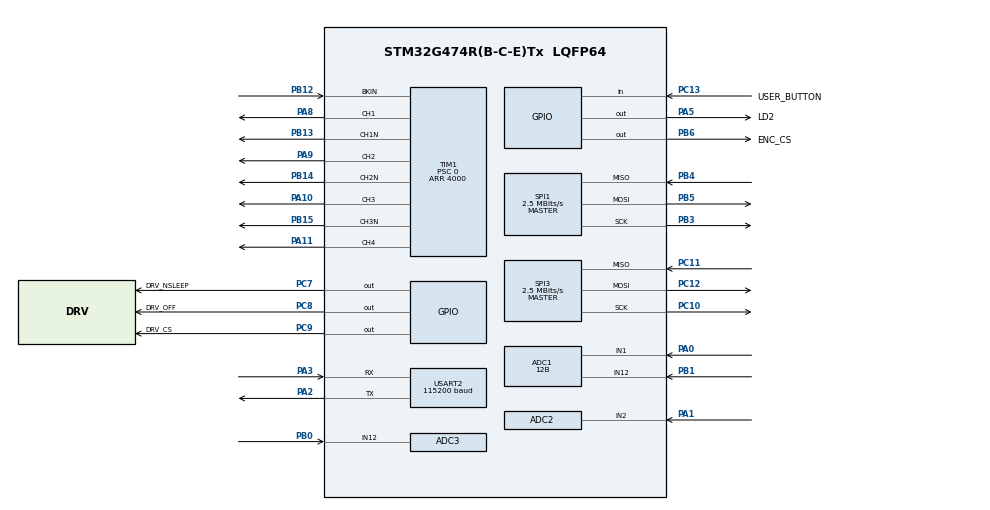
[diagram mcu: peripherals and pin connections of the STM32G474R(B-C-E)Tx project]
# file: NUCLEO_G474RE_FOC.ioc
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ADC1.Channel-1\#ChannelRegularConversion=ADC_CHANNEL_1
ADC1.ClockPrescaler=ADC_CLOCK_ASYNC_DIV1
ADC1.ContinuousConvMode=DISABLE
ADC1.DMAContinuousRequests=DISABLE
ADC1.DataAlign=ADC_DATAALIGN_RIGHT
ADC1.DiscontinuousConvMode=DISABLE
ADC1.EOCSelection=ADC_EOC_SINGLE_CONV
ADC1.EnableAnalogWatchDog1=false
ADC1.EnableAnalogWatchDog2=false
ADC1.EnableAnalogWatchDog3=false
ADC1.EnableInjectedConversion=ENABLE
ADC1.EnableInjectedOversampling=DISABLE
ADC1.EnableRegularConversion=ENABLE
ADC1.ExternalTrigConv=ADC_SOFTWARE_START
ADC1.ExternalTrigConvEdge=ADC_EXTERNALTRIGCONVEDGE_NONE
ADC1.ExternalTrigInjecConv=ADC_EXTERNALTRIGINJEC_T1_TRGO2
ADC1.ExternalTrigInjecConvEdge=ADC_EXTERNALTRIGINJECCONV_EDGE_RISING
ADC1.GainCompensation=0
ADC1.InjNumberOfConversion=2
ADC1.InjectedChannel-1\#ChannelInjectedConversion=ADC_CHANNEL_1
ADC1.InjectedChannel-2\#ChannelInjectedConversion=ADC_CHANNEL_12
ADC1.InjectedConvMode=None
ADC1.InjectedOffsetNumber-1\#ChannelInjectedConversion=ADC_OFFSET_NONE
ADC1.InjectedOffsetNumber-2\#ChannelInjectedConversion=ADC_OFFSET_NONE
ADC1.InjectedRank-1\#ChannelInjectedConversion=1
ADC1.InjectedRank-2\#ChannelInjectedConversion=2
ADC1.InjectedSamplingTime-1\#ChannelInjectedConversion=ADC_SAMPLETIME_12CYCLES_5
ADC1.InjectedSamplingTime-2\#ChannelInjectedConversion=ADC_SAMPLETIME_12CYCLES_5
ADC1.LowPowerAutoWait=DISABLE
ADC1.NbrOfConversion=1
ADC1.OffsetNumber-1\#ChannelRegularConversion=ADC_OFFSET_NONE
ADC1.Overrun=ADC_OVR_DATA_PRESERVED
ADC1.OversamplingMode=DISABLE
ADC1.Rank-1\#ChannelRegularConversion=1
ADC1.Resolution=ADC_RESOLUTION_12B
ADC1.SamplingTime-1\#ChannelRegularConversion=ADC_SAMPLETIME_12CYCLES_5
ADC1.ScanConvMode=ADC_SCAN_ENABLE
ADC1.injectedQueueMode=DISABLE
ADC1.master=1
ADC2.Channel-2\#ChannelRegularConversion=ADC_CHANNEL_2
ADC2.ClockPrescaler=ADC_CLOCK_ASYNC_DIV1
ADC2.ContinuousConvMode=DISABLE
ADC2.DMAContinuousRequests=DISABLE
ADC2.DataAlign=ADC_DATAALIGN_RIGHT
ADC2.DiscontinuousConvMode=DISABLE
ADC2.EOCSelection=ADC_EOC_SINGLE_CONV
ADC2.EnableAnalogWatchDog1=false
ADC2.EnableAnalogWatchDog2=false
ADC2.EnableAnalogWatchDog3=false
ADC2.EnableInjectedConversion=ENABLE
ADC2.EnableInjectedOversampling=DISABLE
ADC2.EnableRegularConversion=ENABLE
ADC2.ExternalTrigConv=ADC_SOFTWARE_START
ADC2.ExternalTrigConvEdge=ADC_EXTERNALTRIGCONVEDGE_NONE
ADC2.ExternalTrigInjecConv=ADC_EXTERNALTRIGINJEC_T1_TRGO2
ADC2.ExternalTrigInjecConvEdge=ADC_EXTERNALTRIGINJECCONV_EDGE_RISING
ADC2.GainCompensation=0
ADC2.InjNumberOfConversion=1
ADC2.InjectedChannel-1\#ChannelInjectedConversion=ADC_CHANNEL_2
ADC2.InjectedConvMode=None
ADC2.InjectedOffsetNumber-1\#ChannelInjectedConversion=ADC_OFFSET_NONE
ADC2.InjectedRank-1\#ChannelInjectedConversion=1
ADC2.InjectedSamplingTime-1\#ChannelInjectedConversion=ADC_SAMPLETIME_12CYCLES_5
ADC2.LowPowerAutoWait=DISABLE
ADC2.NbrOfConversion=1
ADC2.OffsetNumber-2\#ChannelRegularConversion=ADC_OFFSET_NONE
ADC2.Overrun=ADC_OVR_DATA_PRESERVED
ADC2.OversamplingMode=DISABLE
ADC2.Rank-2\#ChannelRegularConversion=1
ADC2.Resolution=ADC_RESOLUTION_12B
ADC2.SamplingTime-2\#ChannelRegularConversion=ADC_SAMPLETIME_12CYCLES_5
ADC2.ScanConvMode=ADC_SCAN_DISABLE
ADC2.injectedQueueMode=DISABLE
ADC3.Channel-12\#ChannelRegularConversion=ADC_CHANNEL_12
ADC3.ClockPrescaler=ADC_CLOCK_ASYNC_DIV1
ADC3.ContinuousConvMode=DISABLE
ADC3.DMAContinuousRequests=DISABLE
ADC3.DataAlign=ADC_DATAALIGN_RIGHT
ADC3.DiscontinuousConvMode=DISABLE
ADC3.EOCSelection=ADC_EOC_SINGLE_CONV
ADC3.EnableAnalogWatchDog1=false
ADC3.EnableAnalogWatchDog2=false
ADC3.EnableAnalogWatchDog3=false
ADC3.EnableInjectedConversion=ENABLE
ADC3.EnableInjectedOversampling=DISABLE
ADC3.EnableRegularConversion=ENABLE
ADC3.ExternalTrigConv=ADC_SOFTWARE_START
ADC3.ExternalTrigConvEdge=ADC_EXTERNALTRIGCONVEDGE_NONE
ADC3.ExternalTrigInjecConv=ADC_EXTERNALTRIGINJEC_T1_TRGO2
ADC3.ExternalTrigInjecConvEdge=ADC_EXTERNALTRIGINJECCONV_EDGE_RISING
ADC3.GainCompensation=0
ADC3.InjNumberOfConversion=1
ADC3.InjectedChannel-1\#ChannelInjectedConversion=ADC_CHANNEL_12
ADC3.InjectedConvMode=None
ADC3.InjectedOffsetNumber-1\#ChannelInjectedConversion=ADC_OFFSET_NONE
ADC3.InjectedRank-1\#ChannelInjectedConversion=1
ADC3.InjectedSamplingTime-1\#ChannelInjectedConversion=ADC_SAMPLETIME_12CYCLES_5
ADC3.LowPowerAutoWait=DISABLE
ADC3.NbrOfConversion=1
ADC3.OffsetNumber-12\#ChannelRegularConversion=ADC_OFFSET_NONE
ADC3.Overrun=ADC_OVR_DATA_PRESERVED
ADC3.OversamplingMode=DISABLE
ADC3.Rank-12\#ChannelRegularConversion=1
ADC3.Resolution=ADC_RESOLUTION_12B
ADC3.SamplingTime-12\#ChannelRegularConversion=ADC_SAMPLETIME_12CYCLES_5
ADC3.ScanConvMode=ADC_SCAN_DISABLE
ADC3.injectedQueueMode=DISABLE
ADC3.master=1
IWDG.Prescaler=IWDG_PRESCALER_32
IWDG.Reload=127
IWDG.Window=4095
Mcu.Family=STM32G4
Mcu.Name=STM32G474R(B-C-E)Tx
Mcu.Package=LQFP64
NVIC.ADC1_2_IRQn=true\:1\:0\:false\:false\:true\:true\:true\:true
NVIC.PriorityGroup=NVIC_PRIORITYGROUP_4
NVIC.TIM1_BRK_TIM15_IRQn=true\:0\:0\:false\:false\:true\:true\:true\:true
NVIC.TIM6_DAC_IRQn=true\:2\:0\:false\:false\:true\:true\:true\:true
NVIC.USART2_IRQn=true\:4\:0\:false\:false\:true\:true\:true\:true
PA0.Mode=IN1-Single-Ended
PA0.Signal=ADC1_IN1
PA1.Mode=IN2-Single-Ended
PA1.Signal=ADC2_IN2
PA10.GPIO_Speed=GPIO_SPEED_FREQ_VERY_HIGH
PA10.Signal=S_TIM1_CH3
PA11.GPIO_Speed=GPIO_SPEED_FREQ_VERY_HIGH
PA11.Signal=S_TIM1_CH4
PA13.Mode=Serial_Wire
PA13.Signal=SYS_JTMS-SWDIO
PA14.Mode=Serial_Wire
PA14.Signal=SYS_JTCK-SWCLK
PA2.Mode=Asynchronous
PA2.Signal=USART2_TX
PA3.Mode=Asynchronous
PA3.Signal=USART2_RX
PA5.GPIO_Label=LD2
PA5.Signal=GPIO_Output
PA8.GPIO_Speed=GPIO_SPEED_FREQ_VERY_HIGH
PA8.Signal=S_TIM1_CH1
PA9.GPIO_Speed=GPIO_SPEED_FREQ_VERY_HIGH
PA9.Signal=S_TIM1_CH2
PB0.Mode=IN12-Single-Ended
PB0.Signal=ADC3_IN12
PB1.Mode=IN12-Single-Ended
PB1.Signal=ADC1_IN12
PB12.GPIO_PuPd=GPIO_PULLUP
PB12.Mode=Activate-Break-Input
PB12.Signal=TIM1_BKIN
PB13.GPIO_Speed=GPIO_SPEED_FREQ_VERY_HIGH
PB13.Mode=PWM Generation1 CH1 CH1N
PB13.Signal=TIM1_CH1N
PB14.GPIO_Speed=GPIO_SPEED_FREQ_VERY_HIGH
PB14.Mode=PWM Generation2 CH2 CH2N
PB14.Signal=TIM1_CH2N
PB15.GPIO_Speed=GPIO_SPEED_FREQ_VERY_HIGH
PB15.Mode=PWM Generation3 CH3 CH3N
PB15.Signal=TIM1_CH3N
PB3.GPIO_PuPd=GPIO_PULLDOWN
PB3.GPIO_Speed=GPIO_SPEED_FREQ_VERY_HIGH
PB3.Mode=Full_Duplex_Master
PB3.Signal=SPI1_SCK
PB4.GPIO_PuPd=GPIO_PULLDOWN
PB4.GPIO_Speed=GPIO_SPEED_FREQ_VERY_HIGH
PB4.Mode=Full_Duplex_Master
PB4.Signal=SPI1_MISO
PB5.GPIO_PuPd=GPIO_PULLDOWN
PB5.GPIO_Speed=GPIO_SPEED_FREQ_VERY_HIGH
PB5.Mode=Full_Duplex_Master
PB5.Signal=SPI1_MOSI
PB6.GPIO_Label=ENC_CS
PB6.GPIO_Speed=GPIO_SPEED_FREQ_HIGH
PB6.PinState=GPIO_PIN_SET
PB6.Signal=GPIO_Output
PC10.GPIO_PuPd=GPIO_PULLDOWN
PC10.GPIO_Speed=GPIO_SPEED_FREQ_LOW
PC10.Mode=Full_Duplex_Master
PC10.Signal=SPI3_SCK
PC11.GPIO_PuPd=GPIO_PULLDOWN
PC11.GPIO_Speed=GPIO_SPEED_FREQ_VERY_HIGH
PC11.Mode=Full_Duplex_Master
PC11.Signal=SPI3_MISO
PC12.GPIO_PuPd=GPIO_PULLDOWN
PC12.GPIO_Speed=GPIO_SPEED_FREQ_LOW
PC12.Mode=Full_Duplex_Master
PC12.Signal=SPI3_MOSI
PC13.GPIO_Label=USER_BUTTON
PC13.Signal=GPIO_Input
PC7.GPIO_Label=DRV_NSLEEP
PC7.GPIO_Speed=GPIO_SPEED_FREQ_HIGH
PC7.PinState=GPIO_PIN_RESET
PC7.Signal=GPIO_Output
PC8.GPIO_Label=DRV_OFF
PC8.GPIO_Speed=GPIO_SPEED_FREQ_HIGH
PC8.PinState=GPIO_PIN_SET
PC8.Signal=GPIO_Output
PC9.GPIO_Label=DRV_CS
PC9.GPIO_Speed=GPIO_SPEED_FREQ_HIGH
PC9.PinState=GPIO_PIN_SET
PC9.Signal=GPIO_Output
ProjectManager.HeapSize=0x200
ProjectManager.StackSize=0x1800
ProjectManager.TargetToolchain=MDK-ARM V5.32
RCC.ADC12ClockSelection=RCC_ADC12CLKSOURCE_PLL
RCC.ADC12Freq_Value=40000000
RCC.ADC345ClockSelection=RCC_ADC345CLKSOURCE_PLL
RCC.ADC345Freq_Value=40000000
RCC.AHBFreq_Value=160000000
RCC.APB1CLKDivider=RCC_HCLK_DIV2
RCC.APB1Freq_Value=80000000
RCC.APB1TimFreq_Value=160000000
RCC.APB2Freq_Value=160000000
RCC.APB2TimFreq_Value=160000000
RCC.CortexFreq_Value=160000000
RCC.EXTERNAL_CLOCK_VALUE=12288000
RCC.HCLKFreq_Value=160000000
RCC.HSE_VALUE=8000000
RCC.HSI48_VALUE=48000000
RCC.HSI_VALUE=16000000
RCC.LSE_VALUE=32768
RCC.PLLM=RCC_PLLM_DIV4
RCC.PLLN=80
RCC.PLLP=RCC_PLLP_DIV8
RCC.PLLQ=RCC_PLLQ_DIV2
RCC.PLLSourceVirtual=RCC_PLLSOURCE_HSI
RCC.SYSCLKFreq_VALUE=160000000
RCC.SYSCLKSource=RCC_SYSCLKSOURCE_PLLCLK
RCC.USBFreq_Value=160000000
RCC.VCOOutputFreq_Value=320000000
SH.S_TIM1_CH1.0=TIM1_CH1,PWM Generation1 CH1 CH1N
SH.S_TIM1_CH2.0=TIM1_CH2,PWM Generation2 CH2 CH2N
SH.S_TIM1_CH3.0=TIM1_CH3,PWM Generation3 CH3 CH3N
SH.S_TIM1_CH4.0=TIM1_CH4,PWM Generation4 CH4
SPI1.BaudRatePrescaler=SPI_BAUDRATEPRESCALER_64
SPI1.CLKPhase=SPI_PHASE_2EDGE
SPI1.CLKPolarity=SPI_POLARITY_LOW
SPI1.CRCCalculation=SPI_CRCCALCULATION_DISABLE
SPI1.CalculateBaudRate=2.5 MBits/s
SPI1.DataSize=SPI_DATASIZE_16BIT
SPI1.Direction=SPI_DIRECTION_2LINES
SPI1.FirstBit=SPI_FIRSTBIT_MSB
SPI1.Mode=SPI_MODE_MASTER
SPI1.NSS=SPI_NSS_SOFT
SPI1.TIMode=SPI_TIMODE_DISABLE
SPI1.VirtualType=VM_MASTER
SPI3.BaudRatePrescaler=SPI_BAUDRATEPRESCALER_32
SPI3.CLKPhase=SPI_PHASE_2EDGE
SPI3.CLKPolarity=SPI_POLARITY_LOW
SPI3.CRCCalculation=SPI_CRCCALCULATION_DISABLE
SPI3.CalculateBaudRate=2.5 MBits/s
SPI3.DataSize=SPI_DATASIZE_16BIT
SPI3.Direction=SPI_DIRECTION_2LINES
SPI3.FirstBit=SPI_FIRSTBIT_MSB
SPI3.Mode=SPI_MODE_MASTER
SPI3.NSS=SPI_NSS_SOFT
SPI3.TIMode=SPI_TIMODE_DISABLE
SPI3.VirtualType=VM_MASTER
TIM1.AsymmetricalDeadTime=DISABLE
TIM1.AutoReloadPreload=TIM_AUTORELOAD_PRELOAD_DISABLE
TIM1.AutomaticOutput=TIM_AUTOMATICOUTPUT_DISABLE
TIM1.Break2Filter=0
TIM1.Break2Polarity=TIM_BREAK2POLARITY_HIGH
TIM1.Break2State=TIM_BREAK2_DISABLE
TIM1.BreakAFMode=TIM_BREAK_AFMODE_INPUT
TIM1.BreakFilter=0
TIM1.BreakPolarity=TIM_BREAKPOLARITY_LOW
TIM1.BreakState=TIM_BREAK_ENABLE
TIM1.Channel-PWM\ Generation1\ CH1\ CH1N=TIM_CHANNEL_1
TIM1.Channel-PWM\ Generation2\ CH2\ CH2N=TIM_CHANNEL_2
TIM1.Channel-PWM\ Generation3\ CH3\ CH3N=TIM_CHANNEL_3
TIM1.Channel-PWM\ Generation4\ CH4=TIM_CHANNEL_4
TIM1.ClearInputSource=TIM_CLEARINPUTSOURCE_NONE
TIM1.ClockDivision=TIM_CLOCKDIVISION_DIV1
TIM1.CounterMode=TIM_COUNTERMODE_CENTERALIGNED1
TIM1.DeadTime=80
TIM1.DeadTimePreload=DISABLE
TIM1.Dithering=Disable
TIM1.LockLevel=TIM_LOCKLEVEL_OFF
TIM1.OCFastMode_PWM-PWM\ Generation1\ CH1\ CH1N=TIM_OCFAST_DISABLE
TIM1.OCFastMode_PWM-PWM\ Generation2\ CH2\ CH2N=TIM_OCFAST_DISABLE
TIM1.OCFastMode_PWM-PWM\ Generation3\ CH3\ CH3N=TIM_OCFAST_DISABLE
TIM1.OCFastMode_PWM-PWM\ Generation4\ CH4=TIM_OCFAST_DISABLE
TIM1.OCIdleState_1=TIM_OCIDLESTATE_RESET
TIM1.OCIdleState_2=TIM_OCIDLESTATE_RESET
TIM1.OCIdleState_3=TIM_OCIDLESTATE_RESET
TIM1.OCIdleState_4=TIM_OCIDLESTATE_RESET
TIM1.OCMode_PWM-PWM\ Generation1\ CH1\ CH1N=TIM_OCMODE_PWM1
TIM1.OCMode_PWM-PWM\ Generation2\ CH2\ CH2N=TIM_OCMODE_PWM1
TIM1.OCMode_PWM-PWM\ Generation3\ CH3\ CH3N=TIM_OCMODE_PWM1
TIM1.OCMode_PWM-PWM\ Generation4\ CH4=TIM_OCMODE_PWM2
TIM1.OCNIdleState_1=TIM_OCNIDLESTATE_RESET
TIM1.OCNIdleState_2=TIM_OCNIDLESTATE_RESET
TIM1.OCNIdleState_3=TIM_OCNIDLESTATE_RESET
TIM1.OCNPolarity_1=TIM_OCNPOLARITY_HIGH
TIM1.OCNPolarity_2=TIM_OCNPOLARITY_HIGH
TIM1.OCNPolarity_3=TIM_OCNPOLARITY_HIGH
TIM1.OCPolarity_1=TIM_OCPOLARITY_HIGH
TIM1.OCPolarity_2=TIM_OCPOLARITY_HIGH
TIM1.OCPolarity_3=TIM_OCPOLARITY_HIGH
TIM1.OCPolarity_4=TIM_OCPOLARITY_HIGH
TIM1.OffStateIDLEMode=TIM_OSSI_ENABLE
TIM1.OffStateRunMode=TIM_OSSR_ENABLE
TIM1.PeriodNoDither=4000
TIM1.Prescaler=0
TIM1.PulseNoDither_1=2000
TIM1.PulseNoDither_2=2000
TIM1.PulseNoDither_3=2000
TIM1.PulseNoDither_4=3900
TIM1.RepetitionCounter=0
TIM1.SourceBRK2COMP1=TIM_BREAKINPUTSOURCE_DISABLE
TIM1.SourceBRK2COMP2=TIM_BREAKINPUTSOURCE_DISABLE
TIM1.SourceBRK2COMP3=TIM_BREAKINPUTSOURCE_DISABLE
TIM1.SourceBRK2COMP4=TIM_BREAKINPUTSOURCE_DISABLE
TIM1.SourceBRK2COMP5=TIM_BREAKINPUTSOURCE_DISABLE
TIM1.SourceBRK2COMP6=TIM_BREAKINPUTSOURCE_DISABLE
TIM1.SourceBRK2COMP7=TIM_BREAKINPUTSOURCE_DISABLE
TIM1.SourceBRK2DigInput=TIM_BREAKINPUTSOURCE_DISABLE
TIM1.SourceBRKCOMP1=TIM_BREAKINPUTSOURCE_DISABLE
TIM1.SourceBRKCOMP2=TIM_BREAKINPUTSOURCE_DISABLE
TIM1.SourceBRKCOMP3=TIM_BREAKINPUTSOURCE_DISABLE
TIM1.SourceBRKCOMP4=TIM_BREAKINPUTSOURCE_DISABLE
TIM1.SourceBRKCOMP5=TIM_BREAKINPUTSOURCE_DISABLE
TIM1.SourceBRKCOMP6=TIM_BREAKINPUTSOURCE_DISABLE
TIM1.SourceBRKCOMP7=TIM_BREAKINPUTSOURCE_DISABLE
TIM1.SourceBRKDigInput=TIM_BREAKINPUTSOURCE_ENABLE
TIM1.SourceBRKDigInputPolarity=TIM_BREAKINPUTSOURCE_POLARITY_HIGH
TIM1.TIM_MasterOutputTrigger=TIM_TRGO_RESET
TIM1.TIM_MasterOutputTrigger2=TIM_TRGO2_OC4REF
TIM1.TIM_MasterSlaveMode=TIM_MASTERSLAVEMODE_DISABLE
TIM2.AutoReloadPreload=TIM_AUTORELOAD_PRELOAD_DISABLE
TIM2.ClockDivision=TIM_CLOCKDIVISION_DIV1
TIM2.CounterMode=TIM_COUNTERMODE_UP
TIM2.Period=4294967295
TIM2.Prescaler=159
TIM2.TIM_MasterOutputTrigger=TIM_TRGO_RESET
TIM2.TIM_MasterSlaveMode=TIM_MASTERSLAVEMODE_DISABLE
TIM2.TIM_SlaveMode=TIM_SLAVEMODE_DISABLE
TIM6.AutoReloadPreload=TIM_AUTORELOAD_PRELOAD_DISABLE
TIM6.Period=249
TIM6.Prescaler=159
USART2.BaudRate=115200
USART2.VirtualMode-Asynchronous=VM_ASYNC
VP_IWDG_VS_IWDG.Mode=IWDG_Activate
VP_SYS_VS_DBSignals.Mode=DisableDeadBatterySignals
VP_TIM2_VS_ClockSourceINT.Mode=Internal
VP_TIM6_VS_ClockSourceINT.Mode=Enable_Timer
board=custom

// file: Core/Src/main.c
/* USER CODE BEGIN Header */
/**
  ******************************************************************************
  * @file           : main.c
  * @brief          : Main program body
  ******************************************************************************
  * @attention
  *
  * Copyright (c) 2026 STMicroelectronics.
  * All rights reserved.
  *
  * This software is licensed under terms that can be found in the LICENSE file
  * in the root directory of this software component.
  * If no LICENSE file comes with this software, it is provided AS-IS.
  *
  ******************************************************************************
  */
/* USER CODE END Header */
#include "main.h"

/* USER CODE BEGIN Includes */
#include "bench_app.h"
/* USER CODE END Includes */

void SystemClock_Config(void);
static void MX_GPIO_Init(void);
static void MX_USART2_UART_Init(void);
static void MX_SPI1_Init(void);
static void MX_SPI3_Init(void);
static void MX_ADC1_Init(void);
static void MX_ADC2_Init(void);
static void MX_ADC3_Init(void);
static void MX_TIM1_Init(void);
static void MX_TIM2_Init(void);
static void MX_TIM6_Init(void);
static void MX_IWDG_Init(void);

int main(void)
{

  /* MCU Configuration--------------------------------------------------------*/

  /* Reset of all peripherals, Initializes the Flash interface and the Systick. */
  LL_APB2_GRP1_EnableClock(LL_APB2_GRP1_PERIPH_SYSCFG);
  LL_APB1_GRP1_EnableClock(LL_APB1_GRP1_PERIPH_PWR);

  /* System interrupt init*/
  NVIC_SetPriorityGrouping(NVIC_PRIORITYGROUP_4);

  /* SysTick_IRQn interrupt configuration */
  NVIC_SetPriority(SysTick_IRQn, NVIC_EncodePriority(NVIC_GetPriorityGrouping(),3, 0));

  /** Disable the internal Pull-Up in Dead Battery pins of UCPD peripheral
  */
  LL_PWR_DisableUCPDDeadBattery();

  /* Configure the system clock */
  SystemClock_Config();

  /* Initialize all configured peripherals */
  MX_GPIO_Init();
  MX_USART2_UART_Init();
  MX_SPI1_Init();
  MX_SPI3_Init();
  MX_ADC1_Init();
  MX_ADC2_Init();
  MX_ADC3_Init();
  MX_TIM1_Init();
  MX_TIM2_Init();
  MX_TIM6_Init();
  MX_IWDG_Init();
  /* USER CODE BEGIN 2 */
  Bench_Init();
  /* USER CODE END 2 */

  /* Infinite loop */
  while (1)
  {

    /* USER CODE BEGIN 3 */
    Bench_Loop();
  }
  /* USER CODE END 3 */
}

void SystemClock_Config(void)
{
  LL_FLASH_SetLatency(LL_FLASH_LATENCY_4);
  while(LL_FLASH_GetLatency() != LL_FLASH_LATENCY_4)
  {
  }
  LL_PWR_EnableRange1BoostMode();
  LL_RCC_HSI_Enable();
   /* Wait till HSI is ready */
  while(LL_RCC_HSI_IsReady() != 1)
  {
  }

  LL_RCC_HSI_SetCalibTrimming(64);
  LL_RCC_LSI_Enable();
   /* Wait till LSI is ready */
  while(LL_RCC_LSI_IsReady() != 1)
  {
  }

  LL_RCC_PLL_ConfigDomain_SYS(LL_RCC_PLLSOURCE_HSI, LL_RCC_PLLM_DIV_4, 80, LL_RCC_PLLR_DIV_2);
  /* ES0430 2.7.11: concurrent ADCs share PLLP, with no ADC prescaling.
   * Keep the ADC at 40 MHz and TIM1 at 160 MHz (20 kHz PWM). */
  LL_RCC_PLL_ConfigDomain_ADC(LL_RCC_PLLSOURCE_HSI, LL_RCC_PLLM_DIV_4, 80, LL_RCC_PLLP_DIV_8);
  LL_RCC_PLL_EnableDomain_ADC();
  LL_RCC_PLL_EnableDomain_SYS();
  LL_RCC_PLL_Enable();
   /* Wait till PLL is ready */
  while(LL_RCC_PLL_IsReady() != 1)
  {
  }

  LL_RCC_SetSysClkSource(LL_RCC_SYS_CLKSOURCE_PLL);
  LL_RCC_SetAHBPrescaler(LL_RCC_SYSCLK_DIV_2);
   /* Wait till System clock is ready */
  while(LL_RCC_GetSysClkSource() != LL_RCC_SYS_CLKSOURCE_STATUS_PLL)
  {
  }

  /* Insure 1us transition state at intermediate medium speed clock*/
  for (__IO uint32_t i = (170 >> 1); i !=0; i--);

  /* Set AHB prescaler*/
  LL_RCC_SetAHBPrescaler(LL_RCC_SYSCLK_DIV_1);
  LL_RCC_SetAPB1Prescaler(LL_RCC_APB1_DIV_2);
  LL_RCC_SetAPB2Prescaler(LL_RCC_APB2_DIV_1);

  LL_Init1msTick(160000000);

  LL_SetSystemCoreClock(160000000);
}

static void MX_ADC1_Init(void)
{

  LL_ADC_InitTypeDef ADC_InitStruct = {0};
  LL_ADC_REG_InitTypeDef ADC_REG_InitStruct = {0};
  LL_ADC_CommonInitTypeDef ADC_CommonInitStruct = {0};
  LL_ADC_INJ_InitTypeDef ADC_INJ_InitStruct = {0};

  LL_GPIO_InitTypeDef GPIO_InitStruct = {0};

  LL_RCC_SetADCClockSource(LL_RCC_ADC12_CLKSOURCE_PLL);

  /* Peripheral clock enable */
  LL_AHB2_GRP1_EnableClock(LL_AHB2_GRP1_PERIPH_ADC12);

  LL_AHB2_GRP1_EnableClock(LL_AHB2_GRP1_PERIPH_GPIOA);
  LL_AHB2_GRP1_EnableClock(LL_AHB2_GRP1_PERIPH_GPIOB);
  /**ADC1 GPIO Configuration
  PA0   ------> ADC1_IN1
  PB1   ------> ADC1_IN12
  */
  GPIO_InitStruct.Pin = LL_GPIO_PIN_0;
  GPIO_InitStruct.Mode = LL_GPIO_MODE_ANALOG;
  GPIO_InitStruct.Pull = LL_GPIO_PULL_NO;
  LL_GPIO_Init(GPIOA, &GPIO_InitStruct);

  GPIO_InitStruct.Pin = LL_GPIO_PIN_1;
  GPIO_InitStruct.Mode = LL_GPIO_MODE_ANALOG;
  GPIO_InitStruct.Pull = LL_GPIO_PULL_NO;
  LL_GPIO_Init(GPIOB, &GPIO_InitStruct);

  /* ADC1 interrupt Init */
  NVIC_SetPriority(ADC1_2_IRQn, NVIC_EncodePriority(NVIC_GetPriorityGrouping(),1, 0));
  NVIC_EnableIRQ(ADC1_2_IRQn);

  /** Common config
  */
  ADC_InitStruct.Resolution = LL_ADC_RESOLUTION_12B;
  ADC_InitStruct.DataAlignment = LL_ADC_DATA_ALIGN_RIGHT;
  ADC_InitStruct.LowPowerMode = LL_ADC_LP_MODE_NONE;
  LL_ADC_Init(ADC1, &ADC_InitStruct);
  ADC_REG_InitStruct.TriggerSource = LL_ADC_REG_TRIG_SOFTWARE;
  ADC_REG_InitStruct.SequencerLength = LL_ADC_REG_SEQ_SCAN_DISABLE;
  ADC_REG_InitStruct.SequencerDiscont = LL_ADC_REG_SEQ_DISCONT_DISABLE;
  ADC_REG_InitStruct.ContinuousMode = LL_ADC_REG_CONV_SINGLE;
  ADC_REG_InitStruct.DMATransfer = LL_ADC_REG_DMA_TRANSFER_NONE;
  ADC_REG_InitStruct.Overrun = LL_ADC_REG_OVR_DATA_PRESERVED;
  LL_ADC_REG_Init(ADC1, &ADC_REG_InitStruct);
  LL_ADC_SetGainCompensation(ADC1, 0);
  LL_ADC_SetOverSamplingScope(ADC1, LL_ADC_OVS_DISABLE);
  ADC_CommonInitStruct.CommonClock = LL_ADC_CLOCK_ASYNC_DIV1;
  ADC_CommonInitStruct.Multimode = LL_ADC_MULTI_INDEPENDENT;
  LL_ADC_CommonInit(__LL_ADC_COMMON_INSTANCE(ADC1), &ADC_CommonInitStruct);
  ADC_INJ_InitStruct.TriggerSource = LL_ADC_INJ_TRIG_EXT_TIM1_TRGO2;
  ADC_INJ_InitStruct.SequencerLength = LL_ADC_INJ_SEQ_SCAN_ENABLE_2RANKS;
  ADC_INJ_InitStruct.SequencerDiscont = LL_ADC_INJ_SEQ_DISCONT_DISABLE;
  ADC_INJ_InitStruct.TrigAuto = LL_ADC_INJ_TRIG_INDEPENDENT;
  LL_ADC_INJ_Init(ADC1, &ADC_INJ_InitStruct);
  LL_ADC_INJ_SetQueueMode(ADC1, LL_ADC_INJ_QUEUE_DISABLE);
  LL_ADC_INJ_SetTriggerEdge(ADC1, LL_ADC_INJ_TRIG_EXT_RISING);

  /* Disable ADC deep power down (enabled by default after reset state) */
  LL_ADC_DisableDeepPowerDown(ADC1);
  /* Enable ADC internal voltage regulator */
  LL_ADC_EnableInternalRegulator(ADC1);
  /* Delay for ADC internal voltage regulator stabilization. */
  /* Compute number of CPU cycles to wait for, from delay in us. */
  /* Note: Variable divided by 2 to compensate partially */
  /* CPU processing cycles (depends on compilation optimization). */
  /* Note: If system core clock frequency is below 200kHz, wait time */
  /* is only a few CPU processing cycles. */
  uint32_t wait_loop_index;
  wait_loop_index = ((LL_ADC_DELAY_INTERNAL_REGUL_STAB_US * (SystemCoreClock / (100000 * 2))) / 10);
  while(wait_loop_index != 0)
  {
    wait_loop_index--;
  }

  /** Configure Injected Channel
  */
  LL_ADC_INJ_SetSequencerRanks(ADC1, LL_ADC_INJ_RANK_1, LL_ADC_CHANNEL_1);
  LL_ADC_SetChannelSamplingTime(ADC1, LL_ADC_CHANNEL_1, LL_ADC_SAMPLINGTIME_12CYCLES_5);
  LL_ADC_SetChannelSingleDiff(ADC1, LL_ADC_CHANNEL_1, LL_ADC_SINGLE_ENDED);

  /** Configure Injected Channel
  */
  LL_ADC_INJ_SetSequencerRanks(ADC1, LL_ADC_INJ_RANK_2, LL_ADC_CHANNEL_12);
  LL_ADC_SetChannelSamplingTime(ADC1, LL_ADC_CHANNEL_12, LL_ADC_SAMPLINGTIME_12CYCLES_5);
  LL_ADC_SetChannelSingleDiff(ADC1, LL_ADC_CHANNEL_12, LL_ADC_SINGLE_ENDED);

  /** Configure Regular Channel
  */
  LL_ADC_REG_SetSequencerRanks(ADC1, LL_ADC_REG_RANK_1, LL_ADC_CHANNEL_1);
  LL_ADC_SetChannelSamplingTime(ADC1, LL_ADC_CHANNEL_1, LL_ADC_SAMPLINGTIME_12CYCLES_5);
  LL_ADC_SetChannelSingleDiff(ADC1, LL_ADC_CHANNEL_1, LL_ADC_SINGLE_ENDED);

}

static void MX_ADC2_Init(void)
{

  LL_ADC_InitTypeDef ADC_InitStruct = {0};
  LL_ADC_REG_InitTypeDef ADC_REG_InitStruct = {0};
  LL_ADC_INJ_InitTypeDef ADC_INJ_InitStruct = {0};

  LL_GPIO_InitTypeDef GPIO_InitStruct = {0};

  LL_RCC_SetADCClockSource(LL_RCC_ADC12_CLKSOURCE_PLL);

  /* Peripheral clock enable */
  LL_AHB2_GRP1_EnableClock(LL_AHB2_GRP1_PERIPH_ADC12);

  LL_AHB2_GRP1_EnableClock(LL_AHB2_GRP1_PERIPH_GPIOA);
  /**ADC2 GPIO Configuration
  PA1   ------> ADC2_IN2
  */
  GPIO_InitStruct.Pin = LL_GPIO_PIN_1;
  GPIO_InitStruct.Mode = LL_GPIO_MODE_ANALOG;
  GPIO_InitStruct.Pull = LL_GPIO_PULL_NO;
  LL_GPIO_Init(GPIOA, &GPIO_InitStruct);

  /* ADC2 interrupt Init */
  NVIC_SetPriority(ADC1_2_IRQn, NVIC_EncodePriority(NVIC_GetPriorityGrouping(),1, 0));
  NVIC_EnableIRQ(ADC1_2_IRQn);

  /** Common config
  */
  ADC_InitStruct.Resolution = LL_ADC_RESOLUTION_12B;
  ADC_InitStruct.DataAlignment = LL_ADC_DATA_ALIGN_RIGHT;
  ADC_InitStruct.LowPowerMode = LL_ADC_LP_MODE_NONE;
  LL_ADC_Init(ADC2, &ADC_InitStruct);
  ADC_REG_InitStruct.TriggerSource = LL_ADC_REG_TRIG_SOFTWARE;
  ADC_REG_InitStruct.SequencerLength = LL_ADC_REG_SEQ_SCAN_DISABLE;
  ADC_REG_InitStruct.SequencerDiscont = LL_ADC_REG_SEQ_DISCONT_DISABLE;
  ADC_REG_InitStruct.ContinuousMode = LL_ADC_REG_CONV_SINGLE;
  ADC_REG_InitStruct.DMATransfer = LL_ADC_REG_DMA_TRANSFER_NONE;
  ADC_REG_InitStruct.Overrun = LL_ADC_REG_OVR_DATA_PRESERVED;
  LL_ADC_REG_Init(ADC2, &ADC_REG_InitStruct);
  LL_ADC_SetGainCompensation(ADC2, 0);
  LL_ADC_SetOverSamplingScope(ADC2, LL_ADC_OVS_DISABLE);
  ADC_INJ_InitStruct.TriggerSource = LL_ADC_INJ_TRIG_EXT_TIM1_TRGO2;
  ADC_INJ_InitStruct.SequencerLength = LL_ADC_INJ_SEQ_SCAN_DISABLE;
  ADC_INJ_InitStruct.SequencerDiscont = LL_ADC_INJ_SEQ_DISCONT_DISABLE;
  ADC_INJ_InitStruct.TrigAuto = LL_ADC_INJ_TRIG_INDEPENDENT;
  LL_ADC_INJ_Init(ADC2, &ADC_INJ_InitStruct);
  LL_ADC_INJ_SetQueueMode(ADC2, LL_ADC_INJ_QUEUE_DISABLE);
  LL_ADC_INJ_SetTriggerEdge(ADC2, LL_ADC_INJ_TRIG_EXT_RISING);

  /* Disable ADC deep power down (enabled by default after reset state) */
  LL_ADC_DisableDeepPowerDown(ADC2);
  /* Enable ADC internal voltage regulator */
  LL_ADC_EnableInternalRegulator(ADC2);
  /* Delay for ADC internal voltage regulator stabilization. */
  /* Compute number of CPU cycles to wait for, from delay in us. */
  /* Note: Variable divided by 2 to compensate partially */
  /* CPU processing cycles (depends on compilation optimization). */
  /* Note: If system core clock frequency is below 200kHz, wait time */
  /* is only a few CPU processing cycles. */
  uint32_t wait_loop_index;
  wait_loop_index = ((LL_ADC_DELAY_INTERNAL_REGUL_STAB_US * (SystemCoreClock / (100000 * 2))) / 10);
  while(wait_loop_index != 0)
  {
    wait_loop_index--;
  }

  /** Configure Injected Channel
  */
  LL_ADC_INJ_SetSequencerRanks(ADC2, LL_ADC_INJ_RANK_1, LL_ADC_CHANNEL_2);
  LL_ADC_SetChannelSamplingTime(ADC2, LL_ADC_CHANNEL_2, LL_ADC_SAMPLINGTIME_12CYCLES_5);
  LL_ADC_SetChannelSingleDiff(ADC2, LL_ADC_CHANNEL_2, LL_ADC_SINGLE_ENDED);

  /** Configure Regular Channel
  */
  LL_ADC_REG_SetSequencerRanks(ADC2, LL_ADC_REG_RANK_1, LL_ADC_CHANNEL_2);
  LL_ADC_SetChannelSamplingTime(ADC2, LL_ADC_CHANNEL_2, LL_ADC_SAMPLINGTIME_12CYCLES_5);
  LL_ADC_SetChannelSingleDiff(ADC2, LL_ADC_CHANNEL_2, LL_ADC_SINGLE_ENDED);

}

static void MX_ADC3_Init(void)
{

  LL_ADC_InitTypeDef ADC_InitStruct = {0};
  LL_ADC_REG_InitTypeDef ADC_REG_InitStruct = {0};
  LL_ADC_CommonInitTypeDef ADC_CommonInitStruct = {0};
  LL_ADC_INJ_InitTypeDef ADC_INJ_InitStruct = {0};

  LL_GPIO_InitTypeDef GPIO_InitStruct = {0};

  LL_RCC_SetADCClockSource(LL_RCC_ADC345_CLKSOURCE_PLL);

  /* Peripheral clock enable */
  LL_AHB2_GRP1_EnableClock(LL_AHB2_GRP1_PERIPH_ADC345);

  LL_AHB2_GRP1_EnableClock(LL_AHB2_GRP1_PERIPH_GPIOB);
  /**ADC3 GPIO Configuration
  PB0   ------> ADC3_IN12
  */
  GPIO_InitStruct.Pin = LL_GPIO_PIN_0;
  GPIO_InitStruct.Mode = LL_GPIO_MODE_ANALOG;
  GPIO_InitStruct.Pull = LL_GPIO_PULL_NO;
  LL_GPIO_Init(GPIOB, &GPIO_InitStruct);

  /** Common config
  */
  ADC_InitStruct.Resolution = LL_ADC_RESOLUTION_12B;
  ADC_InitStruct.DataAlignment = LL_ADC_DATA_ALIGN_RIGHT;
  ADC_InitStruct.LowPowerMode = LL_ADC_LP_MODE_NONE;
  LL_ADC_Init(ADC3, &ADC_InitStruct);
  ADC_REG_InitStruct.TriggerSource = LL_ADC_REG_TRIG_SOFTWARE;
  ADC_REG_InitStruct.SequencerLength = LL_ADC_REG_SEQ_SCAN_DISABLE;
  ADC_REG_InitStruct.SequencerDiscont = LL_ADC_REG_SEQ_DISCONT_DISABLE;
  ADC_REG_InitStruct.ContinuousMode = LL_ADC_REG_CONV_SINGLE;
  ADC_REG_InitStruct.DMATransfer = LL_ADC_REG_DMA_TRANSFER_NONE;
  ADC_REG_InitStruct.Overrun = LL_ADC_REG_OVR_DATA_PRESERVED;
  LL_ADC_REG_Init(ADC3, &ADC_REG_InitStruct);
  LL_ADC_SetGainCompensation(ADC3, 0);
  LL_ADC_SetOverSamplingScope(ADC3, LL_ADC_OVS_DISABLE);
  ADC_CommonInitStruct.CommonClock = LL_ADC_CLOCK_ASYNC_DIV1;
  ADC_CommonInitStruct.Multimode = LL_ADC_MULTI_INDEPENDENT;
  LL_ADC_CommonInit(__LL_ADC_COMMON_INSTANCE(ADC3), &ADC_CommonInitStruct);
  ADC_INJ_InitStruct.TriggerSource = LL_ADC_INJ_TRIG_EXT_TIM1_TRGO2;
  ADC_INJ_InitStruct.SequencerLength = LL_ADC_INJ_SEQ_SCAN_DISABLE;
  ADC_INJ_InitStruct.SequencerDiscont = LL_ADC_INJ_SEQ_DISCONT_DISABLE;
  ADC_INJ_InitStruct.TrigAuto = LL_ADC_INJ_TRIG_INDEPENDENT;
  LL_ADC_INJ_Init(ADC3, &ADC_INJ_InitStruct);
  LL_ADC_INJ_SetQueueMode(ADC3, LL_ADC_INJ_QUEUE_DISABLE);
  LL_ADC_INJ_SetTriggerEdge(ADC3, LL_ADC_INJ_TRIG_EXT_RISING);

  /* Disable ADC deep power down (enabled by default after reset state) */
  LL_ADC_DisableDeepPowerDown(ADC3);
  /* Enable ADC internal voltage regulator */
  LL_ADC_EnableInternalRegulator(ADC3);
  /* Delay for ADC internal voltage regulator stabilization. */
  /* Compute number of CPU cycles to wait for, from delay in us. */
  /* Note: Variable divided by 2 to compensate partially */
  /* CPU processing cycles (depends on compilation optimization). */
  /* Note: If system core clock frequency is below 200kHz, wait time */
  /* is only a few CPU processing cycles. */
  uint32_t wait_loop_index;
  wait_loop_index = ((LL_ADC_DELAY_INTERNAL_REGUL_STAB_US * (SystemCoreClock / (100000 * 2))) / 10);
  while(wait_loop_index != 0)
  {
    wait_loop_index--;
  }

  /** Configure Injected Channel
  */
  LL_ADC_INJ_SetSequencerRanks(ADC3, LL_ADC_INJ_RANK_1, LL_ADC_CHANNEL_12);
  LL_ADC_SetChannelSamplingTime(ADC3, LL_ADC_CHANNEL_12, LL_ADC_SAMPLINGTIME_12CYCLES_5);
  LL_ADC_SetChannelSingleDiff(ADC3, LL_ADC_CHANNEL_12, LL_ADC_SINGLE_ENDED);

  /** Configure Regular Channel
  */
  LL_ADC_REG_SetSequencerRanks(ADC3, LL_ADC_REG_RANK_1, LL_ADC_CHANNEL_12);
  LL_ADC_SetChannelSamplingTime(ADC3, LL_ADC_CHANNEL_12, LL_ADC_SAMPLINGTIME_12CYCLES_5);
  LL_ADC_SetChannelSingleDiff(ADC3, LL_ADC_CHANNEL_12, LL_ADC_SINGLE_ENDED);

}

static void MX_IWDG_Init(void)
{

  LL_IWDG_Enable(IWDG);
  LL_IWDG_EnableWriteAccess(IWDG);
  LL_IWDG_SetPrescaler(IWDG, LL_IWDG_PRESCALER_32);
  LL_IWDG_SetReloadCounter(IWDG, 127);
  while (LL_IWDG_IsReady(IWDG) != 1)
  {
  }

  LL_IWDG_ReloadCounter(IWDG);

}

static void MX_SPI1_Init(void)
{

  LL_SPI_InitTypeDef SPI_InitStruct = {0};

  LL_GPIO_InitTypeDef GPIO_InitStruct = {0};

  /* Peripheral clock enable */
  LL_APB2_GRP1_EnableClock(LL_APB2_GRP1_PERIPH_SPI1);

  LL_AHB2_GRP1_EnableClock(LL_AHB2_GRP1_PERIPH_GPIOB);
  /**SPI1 GPIO Configuration
  PB3   ------> SPI1_SCK
  PB4   ------> SPI1_MISO
  PB5   ------> SPI1_MOSI
  */
  GPIO_InitStruct.Pin = LL_GPIO_PIN_3;
  GPIO_InitStruct.Mode = LL_GPIO_MODE_ALTERNATE;
  GPIO_InitStruct.Speed = LL_GPIO_SPEED_FREQ_LOW;
  GPIO_InitStruct.OutputType = LL_GPIO_OUTPUT_PUSHPULL;
  GPIO_InitStruct.Pull = LL_GPIO_PULL_DOWN;
  GPIO_InitStruct.Alternate = LL_GPIO_AF_5;
  LL_GPIO_Init(GPIOB, &GPIO_InitStruct);

  GPIO_InitStruct.Pin = LL_GPIO_PIN_4;
  GPIO_InitStruct.Mode = LL_GPIO_MODE_ALTERNATE;
  GPIO_InitStruct.Speed = LL_GPIO_SPEED_FREQ_LOW;
  GPIO_InitStruct.OutputType = LL_GPIO_OUTPUT_PUSHPULL;
  GPIO_InitStruct.Pull = LL_GPIO_PULL_DOWN;
  GPIO_InitStruct.Alternate = LL_GPIO_AF_5;
  LL_GPIO_Init(GPIOB, &GPIO_InitStruct);

  GPIO_InitStruct.Pin = LL_GPIO_PIN_5;
  GPIO_InitStruct.Mode = LL_GPIO_MODE_ALTERNATE;
  GPIO_InitStruct.Speed = LL_GPIO_SPEED_FREQ_LOW;
  GPIO_InitStruct.OutputType = LL_GPIO_OUTPUT_PUSHPULL;
  GPIO_InitStruct.Pull = LL_GPIO_PULL_DOWN;
  GPIO_InitStruct.Alternate = LL_GPIO_AF_5;
  LL_GPIO_Init(GPIOB, &GPIO_InitStruct);

  /* SPI1 parameter configuration*/
  SPI_InitStruct.TransferDirection = LL_SPI_FULL_DUPLEX;
  SPI_InitStruct.Mode = LL_SPI_MODE_MASTER;
  SPI_InitStruct.DataWidth = LL_SPI_DATAWIDTH_16BIT;
  SPI_InitStruct.ClockPolarity = LL_SPI_POLARITY_LOW;
  SPI_InitStruct.ClockPhase = LL_SPI_PHASE_2EDGE;
  SPI_InitStruct.NSS = LL_SPI_NSS_SOFT;
  SPI_InitStruct.BaudRate = LL_SPI_BAUDRATEPRESCALER_DIV64;
  SPI_InitStruct.BitOrder = LL_SPI_MSB_FIRST;
  SPI_InitStruct.CRCCalculation = LL_SPI_CRCCALCULATION_DISABLE;
  SPI_InitStruct.CRCPoly = 7;
  LL_SPI_Init(SPI1, &SPI_InitStruct);
  LL_SPI_SetStandard(SPI1, LL_SPI_PROTOCOL_MOTOROLA);
  LL_SPI_DisableNSSPulseMgt(SPI1);

}

static void MX_SPI3_Init(void)
{

  LL_SPI_InitTypeDef SPI_InitStruct = {0};

  LL_GPIO_InitTypeDef GPIO_InitStruct = {0};

  /* Peripheral clock enable */
  LL_APB1_GRP1_EnableClock(LL_APB1_GRP1_PERIPH_SPI3);

  LL_AHB2_GRP1_EnableClock(LL_AHB2_GRP1_PERIPH_GPIOC);
  /**SPI3 GPIO Configuration
  PC10   ------> SPI3_SCK
  PC11   ------> SPI3_MISO
  PC12   ------> SPI3_MOSI
  */
  GPIO_InitStruct.Pin = LL_GPIO_PIN_10;
  GPIO_InitStruct.Mode = LL_GPIO_MODE_ALTERNATE;
  GPIO_InitStruct.Speed = LL_GPIO_SPEED_FREQ_LOW;
  GPIO_InitStruct.OutputType = LL_GPIO_OUTPUT_PUSHPULL;
  GPIO_InitStruct.Pull = LL_GPIO_PULL_DOWN;
  GPIO_InitStruct.Alternate = LL_GPIO_AF_6;
  LL_GPIO_Init(GPIOC, &GPIO_InitStruct);

  GPIO_InitStruct.Pin = LL_GPIO_PIN_11;
  GPIO_InitStruct.Mode = LL_GPIO_MODE_ALTERNATE;
  GPIO_InitStruct.Speed = LL_GPIO_SPEED_FREQ_VERY_HIGH;
  GPIO_InitStruct.OutputType = LL_GPIO_OUTPUT_PUSHPULL;
  GPIO_InitStruct.Pull = LL_GPIO_PULL_DOWN;
  GPIO_InitStruct.Alternate = LL_GPIO_AF_6;
  LL_GPIO_Init(GPIOC, &GPIO_InitStruct);

  GPIO_InitStruct.Pin = LL_GPIO_PIN_12;
  GPIO_InitStruct.Mode = LL_GPIO_MODE_ALTERNATE;
  GPIO_InitStruct.Speed = LL_GPIO_SPEED_FREQ_LOW;
  GPIO_InitStruct.OutputType = LL_GPIO_OUTPUT_PUSHPULL;
  GPIO_InitStruct.Pull = LL_GPIO_PULL_DOWN;
  GPIO_InitStruct.Alternate = LL_GPIO_AF_6;
  LL_GPIO_Init(GPIOC, &GPIO_InitStruct);

  /* SPI3 parameter configuration*/
  SPI_InitStruct.TransferDirection = LL_SPI_FULL_DUPLEX;
  SPI_InitStruct.Mode = LL_SPI_MODE_MASTER;
  SPI_InitStruct.DataWidth = LL_SPI_DATAWIDTH_16BIT;
  SPI_InitStruct.ClockPolarity = LL_SPI_POLARITY_LOW;
  SPI_InitStruct.ClockPhase = LL_SPI_PHASE_2EDGE;
  SPI_InitStruct.NSS = LL_SPI_NSS_SOFT;
  SPI_InitStruct.BaudRate = LL_SPI_BAUDRATEPRESCALER_DIV32;
  SPI_InitStruct.BitOrder = LL_SPI_MSB_FIRST;
  SPI_InitStruct.CRCCalculation = LL_SPI_CRCCALCULATION_DISABLE;
  SPI_InitStruct.CRCPoly = 7;
  LL_SPI_Init(SPI3, &SPI_InitStruct);
  LL_SPI_SetStandard(SPI3, LL_SPI_PROTOCOL_MOTOROLA);
  LL_SPI_DisableNSSPulseMgt(SPI3);

}

static void MX_TIM1_Init(void)
{

  LL_TIM_InitTypeDef TIM_InitStruct = {0};
  LL_TIM_OC_InitTypeDef TIM_OC_InitStruct = {0};
  LL_TIM_BDTR_InitTypeDef TIM_BDTRInitStruct = {0};

  LL_GPIO_InitTypeDef GPIO_InitStruct = {0};

  /* Peripheral clock enable */
  LL_APB2_GRP1_EnableClock(LL_APB2_GRP1_PERIPH_TIM1);

  LL_AHB2_GRP1_EnableClock(LL_AHB2_GRP1_PERIPH_GPIOB);
  /**TIM1 GPIO Configuration
  PB12   ------> TIM1_BKIN
  */
  GPIO_InitStruct.Pin = LL_GPIO_PIN_12;
  GPIO_InitStruct.Mode = LL_GPIO_MODE_ALTERNATE;
  GPIO_InitStruct.Speed = LL_GPIO_SPEED_FREQ_LOW;
  GPIO_InitStruct.OutputType = LL_GPIO_OUTPUT_OPENDRAIN;
  GPIO_InitStruct.Pull = LL_GPIO_PULL_UP;
  GPIO_InitStruct.Alternate = LL_GPIO_AF_6;
  LL_GPIO_Init(GPIOB, &GPIO_InitStruct);

  /* TIM1 interrupt Init */
  NVIC_SetPriority(TIM1_BRK_TIM15_IRQn, NVIC_EncodePriority(NVIC_GetPriorityGrouping(),0, 0));
  NVIC_EnableIRQ(TIM1_BRK_TIM15_IRQn);

  TIM_InitStruct.Prescaler = 0;
  TIM_InitStruct.CounterMode = LL_TIM_COUNTERMODE_CENTER_DOWN;
  TIM_InitStruct.Autoreload = 4000;
  TIM_InitStruct.ClockDivision = LL_TIM_CLOCKDIVISION_DIV1;
  TIM_InitStruct.RepetitionCounter = 0;
  LL_TIM_Init(TIM1, &TIM_InitStruct);
  LL_TIM_DisableARRPreload(TIM1);
  LL_TIM_OC_EnablePreload(TIM1, LL_TIM_CHANNEL_CH1);
  TIM_OC_InitStruct.OCMode = LL_TIM_OCMODE_PWM1;
  TIM_OC_InitStruct.OCState = LL_TIM_OCSTATE_DISABLE;
  TIM_OC_InitStruct.OCNState = LL_TIM_OCSTATE_DISABLE;
  TIM_OC_InitStruct.CompareValue = 2000;
  TIM_OC_InitStruct.OCPolarity = LL_TIM_OCPOLARITY_HIGH;
  TIM_OC_InitStruct.OCNPolarity = LL_TIM_OCPOLARITY_HIGH;
  TIM_OC_InitStruct.OCIdleState = LL_TIM_OCIDLESTATE_LOW;
  TIM_OC_InitStruct.OCNIdleState = LL_TIM_OCIDLESTATE_LOW;
  LL_TIM_OC_Init(TIM1, LL_TIM_CHANNEL_CH1, &TIM_OC_InitStruct);
  LL_TIM_OC_DisableFast(TIM1, LL_TIM_CHANNEL_CH1);
  LL_TIM_OC_EnablePreload(TIM1, LL_TIM_CHANNEL_CH2);
  LL_TIM_OC_Init(TIM1, LL_TIM_CHANNEL_CH2, &TIM_OC_InitStruct);
  LL_TIM_OC_DisableFast(TIM1, LL_TIM_CHANNEL_CH2);
  LL_TIM_OC_EnablePreload(TIM1, LL_TIM_CHANNEL_CH3);
  LL_TIM_OC_Init(TIM1, LL_TIM_CHANNEL_CH3, &TIM_OC_InitStruct);
  LL_TIM_OC_DisableFast(TIM1, LL_TIM_CHANNEL_CH3);
  LL_TIM_OC_EnablePreload(TIM1, LL_TIM_CHANNEL_CH4);
  TIM_OC_InitStruct.OCMode = LL_TIM_OCMODE_PWM2;
  TIM_OC_InitStruct.CompareValue = 3900;
  LL_TIM_OC_Init(TIM1, LL_TIM_CHANNEL_CH4, &TIM_OC_InitStruct);
  LL_TIM_OC_DisableFast(TIM1, LL_TIM_CHANNEL_CH4);
  LL_TIM_SetTriggerOutput(TIM1, LL_TIM_TRGO_RESET);
  LL_TIM_SetTriggerOutput2(TIM1, LL_TIM_TRGO2_OC4);
  LL_TIM_DisableMasterSlaveMode(TIM1);
  LL_TIM_SetBreakInputSourcePolarity(TIM1, LL_TIM_BREAK_INPUT_BKIN, LL_TIM_BKIN_SOURCE_BKIN, LL_TIM_BKIN_POLARITY_HIGH);
  TIM_BDTRInitStruct.OSSRState = LL_TIM_OSSR_ENABLE;
  TIM_BDTRInitStruct.OSSIState = LL_TIM_OSSI_ENABLE;
  TIM_BDTRInitStruct.LockLevel = LL_TIM_LOCKLEVEL_OFF;
  TIM_BDTRInitStruct.DeadTime = 80;
  TIM_BDTRInitStruct.BreakState = LL_TIM_BREAK_ENABLE;
  TIM_BDTRInitStruct.BreakPolarity = LL_TIM_BREAK_POLARITY_LOW;
  TIM_BDTRInitStruct.BreakFilter = LL_TIM_BREAK_FILTER_FDIV1;
  TIM_BDTRInitStruct.BreakAFMode = LL_TIM_BREAK_AFMODE_INPUT;
  TIM_BDTRInitStruct.Break2State = LL_TIM_BREAK2_DISABLE;
  TIM_BDTRInitStruct.Break2Polarity = LL_TIM_BREAK2_POLARITY_HIGH;
  TIM_BDTRInitStruct.Break2Filter = LL_TIM_BREAK2_FILTER_FDIV1;
  TIM_BDTRInitStruct.Break2AFMode = LL_TIM_BREAK_AFMODE_INPUT;
  TIM_BDTRInitStruct.AutomaticOutput = LL_TIM_AUTOMATICOUTPUT_DISABLE;
  LL_TIM_BDTR_Init(TIM1, &TIM_BDTRInitStruct);
  LL_AHB2_GRP1_EnableClock(LL_AHB2_GRP1_PERIPH_GPIOB);
  LL_AHB2_GRP1_EnableClock(LL_AHB2_GRP1_PERIPH_GPIOA);
  /**TIM1 GPIO Configuration
  PB13   ------> TIM1_CH1N
  PB14   ------> TIM1_CH2N
  PB15   ------> TIM1_CH3N
  PA8   ------> TIM1_CH1
  PA9   ------> TIM1_CH2
  PA10   ------> TIM1_CH3
  PA11   ------> TIM1_CH4
  */
  GPIO_InitStruct.Pin = LL_GPIO_PIN_13;
  GPIO_InitStruct.Mode = LL_GPIO_MODE_ALTERNATE;
  GPIO_InitStruct.Speed = LL_GPIO_SPEED_FREQ_VERY_HIGH;
  GPIO_InitStruct.OutputType = LL_GPIO_OUTPUT_PUSHPULL;
  GPIO_InitStruct.Pull = LL_GPIO_PULL_NO;
  GPIO_InitStruct.Alternate = LL_GPIO_AF_6;
  LL_GPIO_Init(GPIOB, &GPIO_InitStruct);

  GPIO_InitStruct.Pin = LL_GPIO_PIN_14;
  GPIO_InitStruct.Mode = LL_GPIO_MODE_ALTERNATE;
  GPIO_InitStruct.Speed = LL_GPIO_SPEED_FREQ_VERY_HIGH;
  GPIO_InitStruct.OutputType = LL_GPIO_OUTPUT_PUSHPULL;
  GPIO_InitStruct.Pull = LL_GPIO_PULL_NO;
  GPIO_InitStruct.Alternate = LL_GPIO_AF_6;
  LL_GPIO_Init(GPIOB, &GPIO_InitStruct);

  GPIO_InitStruct.Pin = LL_GPIO_PIN_15;
  GPIO_InitStruct.Mode = LL_GPIO_MODE_ALTERNATE;
  GPIO_InitStruct.Speed = LL_GPIO_SPEED_FREQ_VERY_HIGH;
  GPIO_InitStruct.OutputType = LL_GPIO_OUTPUT_PUSHPULL;
  GPIO_InitStruct.Pull = LL_GPIO_PULL_NO;
  GPIO_InitStruct.Alternate = LL_GPIO_AF_4;
  LL_GPIO_Init(GPIOB, &GPIO_InitStruct);

  GPIO_InitStruct.Pin = LL_GPIO_PIN_8;
  GPIO_InitStruct.Mode = LL_GPIO_MODE_ALTERNATE;
  GPIO_InitStruct.Speed = LL_GPIO_SPEED_FREQ_VERY_HIGH;
  GPIO_InitStruct.OutputType = LL_GPIO_OUTPUT_PUSHPULL;
  GPIO_InitStruct.Pull = LL_GPIO_PULL_NO;
  GPIO_InitStruct.Alternate = LL_GPIO_AF_6;
  LL_GPIO_Init(GPIOA, &GPIO_InitStruct);

  GPIO_InitStruct.Pin = LL_GPIO_PIN_9;
  GPIO_InitStruct.Mode = LL_GPIO_MODE_ALTERNATE;
  GPIO_InitStruct.Speed = LL_GPIO_SPEED_FREQ_VERY_HIGH;
  GPIO_InitStruct.OutputType = LL_GPIO_OUTPUT_PUSHPULL;
  GPIO_InitStruct.Pull = LL_GPIO_PULL_NO;
  GPIO_InitStruct.Alternate = LL_GPIO_AF_6;
  LL_GPIO_Init(GPIOA, &GPIO_InitStruct);

  GPIO_InitStruct.Pin = LL_GPIO_PIN_10;
  GPIO_InitStruct.Mode = LL_GPIO_MODE_ALTERNATE;
  GPIO_InitStruct.Speed = LL_GPIO_SPEED_FREQ_VERY_HIGH;
  GPIO_InitStruct.OutputType = LL_GPIO_OUTPUT_PUSHPULL;
  GPIO_InitStruct.Pull = LL_GPIO_PULL_NO;
  GPIO_InitStruct.Alternate = LL_GPIO_AF_6;
  LL_GPIO_Init(GPIOA, &GPIO_InitStruct);

  GPIO_InitStruct.Pin = LL_GPIO_PIN_11;
  GPIO_InitStruct.Mode = LL_GPIO_MODE_ALTERNATE;
  GPIO_InitStruct.Speed = LL_GPIO_SPEED_FREQ_VERY_HIGH;
  GPIO_InitStruct.OutputType = LL_GPIO_OUTPUT_PUSHPULL;
  GPIO_InitStruct.Pull = LL_GPIO_PULL_NO;
  GPIO_InitStruct.Alternate = LL_GPIO_AF_11;
  LL_GPIO_Init(GPIOA, &GPIO_InitStruct);

}

static void MX_TIM2_Init(void)
{

  LL_TIM_InitTypeDef TIM_InitStruct = {0};

  /* Peripheral clock enable */
  LL_APB1_GRP1_EnableClock(LL_APB1_GRP1_PERIPH_TIM2);

  TIM_InitStruct.Prescaler = 159;
  TIM_InitStruct.CounterMode = LL_TIM_COUNTERMODE_UP;
  TIM_InitStruct.Autoreload = 4294967295;
  TIM_InitStruct.ClockDivision = LL_TIM_CLOCKDIVISION_DIV1;
  LL_TIM_Init(TIM2, &TIM_InitStruct);
  LL_TIM_DisableARRPreload(TIM2);
  LL_TIM_SetClockSource(TIM2, LL_TIM_CLOCKSOURCE_INTERNAL);
  LL_TIM_SetTriggerOutput(TIM2, LL_TIM_TRGO_RESET);
  LL_TIM_DisableMasterSlaveMode(TIM2);

}

static void MX_TIM6_Init(void)
{

  LL_TIM_InitTypeDef TIM_InitStruct = {0};

  /* Peripheral clock enable */
  LL_APB1_GRP1_EnableClock(LL_APB1_GRP1_PERIPH_TIM6);

  /* TIM6 interrupt Init */
  NVIC_SetPriority(TIM6_DAC_IRQn, NVIC_EncodePriority(NVIC_GetPriorityGrouping(),2, 0));
  NVIC_EnableIRQ(TIM6_DAC_IRQn);

  TIM_InitStruct.Prescaler = 159;
  TIM_InitStruct.CounterMode = LL_TIM_COUNTERMODE_UP;
  TIM_InitStruct.Autoreload = 249;
  LL_TIM_Init(TIM6, &TIM_InitStruct);
  LL_TIM_DisableARRPreload(TIM6);
  LL_TIM_SetTriggerOutput(TIM6, LL_TIM_TRGO_RESET);
  LL_TIM_DisableMasterSlaveMode(TIM6);

}

static void MX_USART2_UART_Init(void)
{

  LL_USART_InitTypeDef USART_InitStruct = {0};

  LL_GPIO_InitTypeDef GPIO_InitStruct = {0};

  LL_RCC_SetUSARTClockSource(LL_RCC_USART2_CLKSOURCE_PCLK1);

  /* Peripheral clock enable */
  LL_APB1_GRP1_EnableClock(LL_APB1_GRP1_PERIPH_USART2);

  LL_AHB2_GRP1_EnableClock(LL_AHB2_GRP1_PERIPH_GPIOA);
  /**USART2 GPIO Configuration
  PA2   ------> USART2_TX
  PA3   ------> USART2_RX
  */
  GPIO_InitStruct.Pin = LL_GPIO_PIN_2;
  GPIO_InitStruct.Mode = LL_GPIO_MODE_ALTERNATE;
  GPIO_InitStruct.Speed = LL_GPIO_SPEED_FREQ_LOW;
  GPIO_InitStruct.OutputType = LL_GPIO_OUTPUT_PUSHPULL;
  GPIO_InitStruct.Pull = LL_GPIO_PULL_NO;
  GPIO_InitStruct.Alternate = LL_GPIO_AF_7;
  LL_GPIO_Init(GPIOA, &GPIO_InitStruct);

  GPIO_InitStruct.Pin = LL_GPIO_PIN_3;
  GPIO_InitStruct.Mode = LL_GPIO_MODE_ALTERNATE;
  GPIO_InitStruct.Speed = LL_GPIO_SPEED_FREQ_LOW;
  GPIO_InitStruct.OutputType = LL_GPIO_OUTPUT_PUSHPULL;
  GPIO_InitStruct.Pull = LL_GPIO_PULL_NO;
  GPIO_InitStruct.Alternate = LL_GPIO_AF_7;
  LL_GPIO_Init(GPIOA, &GPIO_InitStruct);

  /* USART2 interrupt Init */
  NVIC_SetPriority(USART2_IRQn, NVIC_EncodePriority(NVIC_GetPriorityGrouping(),4, 0));
  NVIC_EnableIRQ(USART2_IRQn);

  USART_InitStruct.PrescalerValue = LL_USART_PRESCALER_DIV1;
  USART_InitStruct.BaudRate = 115200;
  USART_InitStruct.DataWidth = LL_USART_DATAWIDTH_8B;
  USART_InitStruct.StopBits = LL_USART_STOPBITS_1;
  USART_InitStruct.Parity = LL_USART_PARITY_NONE;
  USART_InitStruct.TransferDirection = LL_USART_DIRECTION_TX_RX;
  USART_InitStruct.HardwareFlowControl = LL_USART_HWCONTROL_NONE;
  USART_InitStruct.OverSampling = LL_USART_OVERSAMPLING_16;
  LL_USART_Init(USART2, &USART_InitStruct);
  LL_USART_SetTXFIFOThreshold(USART2, LL_USART_FIFOTHRESHOLD_1_8);
  LL_USART_SetRXFIFOThreshold(USART2, LL_USART_FIFOTHRESHOLD_1_8);
  LL_USART_DisableFIFO(USART2);
  LL_USART_ConfigAsyncMode(USART2);

  LL_USART_Enable(USART2);

  /* Polling USART2 initialisation */
  while((!(LL_USART_IsActiveFlag_TEACK(USART2))) || (!(LL_USART_IsActiveFlag_REACK(USART2))))
  {
  }

}

static void MX_GPIO_Init(void)
{
  LL_GPIO_InitTypeDef GPIO_InitStruct = {0};

  /* GPIO Ports Clock Enable */
  LL_AHB2_GRP1_EnableClock(LL_AHB2_GRP1_PERIPH_GPIOC);
  LL_AHB2_GRP1_EnableClock(LL_AHB2_GRP1_PERIPH_GPIOA);
  LL_AHB2_GRP1_EnableClock(LL_AHB2_GRP1_PERIPH_GPIOB);

  /**/
  LL_GPIO_ResetOutputPin(LD2_GPIO_Port, LD2_Pin);

  /**/
  LL_GPIO_ResetOutputPin(DRV_NSLEEP_GPIO_Port, DRV_NSLEEP_Pin);

  /**/
  LL_GPIO_SetOutputPin(DRV_OFF_GPIO_Port, DRV_OFF_Pin);

  /**/
  LL_GPIO_SetOutputPin(DRV_CS_GPIO_Port, DRV_CS_Pin);

  /**/
  LL_GPIO_SetOutputPin(ENC_CS_GPIO_Port, ENC_CS_Pin);

  /**/
  GPIO_InitStruct.Pin = USER_BUTTON_Pin;
  GPIO_InitStruct.Mode = LL_GPIO_MODE_INPUT;
  GPIO_InitStruct.Pull = LL_GPIO_PULL_NO;
  LL_GPIO_Init(USER_BUTTON_GPIO_Port, &GPIO_InitStruct);

  /**/
  GPIO_InitStruct.Pin = LD2_Pin;
  GPIO_InitStruct.Mode = LL_GPIO_MODE_OUTPUT;
  GPIO_InitStruct.Speed = LL_GPIO_SPEED_FREQ_LOW;
  GPIO_InitStruct.OutputType = LL_GPIO_OUTPUT_PUSHPULL;
  GPIO_InitStruct.Pull = LL_GPIO_PULL_NO;
  LL_GPIO_Init(LD2_GPIO_Port, &GPIO_InitStruct);

  /**/
  GPIO_InitStruct.Pin = DRV_NSLEEP_Pin;
  GPIO_InitStruct.Mode = LL_GPIO_MODE_OUTPUT;
  GPIO_InitStruct.Speed = LL_GPIO_SPEED_FREQ_HIGH;
  GPIO_InitStruct.OutputType = LL_GPIO_OUTPUT_PUSHPULL;
  GPIO_InitStruct.Pull = LL_GPIO_PULL_NO;
  LL_GPIO_Init(DRV_NSLEEP_GPIO_Port, &GPIO_InitStruct);

  /**/
  GPIO_InitStruct.Pin = DRV_OFF_Pin;
  GPIO_InitStruct.Mode = LL_GPIO_MODE_OUTPUT;
  GPIO_InitStruct.Speed = LL_GPIO_SPEED_FREQ_HIGH;
  GPIO_InitStruct.OutputType = LL_GPIO_OUTPUT_PUSHPULL;
  GPIO_InitStruct.Pull = LL_GPIO_PULL_NO;
  LL_GPIO_Init(DRV_OFF_GPIO_Port, &GPIO_InitStruct);

  /**/
  GPIO_InitStruct.Pin = DRV_CS_Pin;
  GPIO_InitStruct.Mode = LL_GPIO_MODE_OUTPUT;
  GPIO_InitStruct.Speed = LL_GPIO_SPEED_FREQ_HIGH;
  GPIO_InitStruct.OutputType = LL_GPIO_OUTPUT_PUSHPULL;
  GPIO_InitStruct.Pull = LL_GPIO_PULL_NO;
  LL_GPIO_Init(DRV_CS_GPIO_Port, &GPIO_InitStruct);

  /**/
  GPIO_InitStruct.Pin = ENC_CS_Pin;
  GPIO_InitStruct.Mode = LL_GPIO_MODE_OUTPUT;
  GPIO_InitStruct.Speed = LL_GPIO_SPEED_FREQ_HIGH;
  GPIO_InitStruct.OutputType = LL_GPIO_OUTPUT_PUSHPULL;
  GPIO_InitStruct.Pull = LL_GPIO_PULL_NO;
  LL_GPIO_Init(ENC_CS_GPIO_Port, &GPIO_InitStruct);

}

void Error_Handler(void)
{
  /* USER CODE BEGIN Error_Handler_Debug */
  Bench_Fatal();
  /* User can add his own implementation to report the HAL error return state */
  __disable_irq();
  while (1)
  {
  }
  /* USER CODE END Error_Handler_Debug */
}
